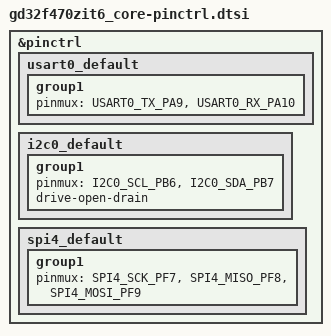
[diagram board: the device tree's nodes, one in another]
/*
 * Copyright (c) 2026 Zhijian Han
 * SPDX-License-Identifier: Apache-2.0
 */

#include <dt-bindings/pinctrl/gd32f470z(e-g-i-k)xx-pinctrl.h>

&pinctrl {
	usart0_default: usart0_default {
		group1 {
			pinmux = <USART0_TX_PA9>, <USART0_RX_PA10>;
		};
	};

	i2c0_default: i2c0_default {
		group1 {
			pinmux = <I2C0_SCL_PB6>, <I2C0_SDA_PB7>;
			drive-open-drain;
		};
	};

	spi4_default: spi4_default {
		group1 {
			pinmux = <SPI4_SCK_PF7>, <SPI4_MISO_PF8>, <SPI4_MOSI_PF9>;
		};
	};
};
